AUTOSAR XML (schema 4-2-2)
package /STELLANTIS/EPT/ASWCs
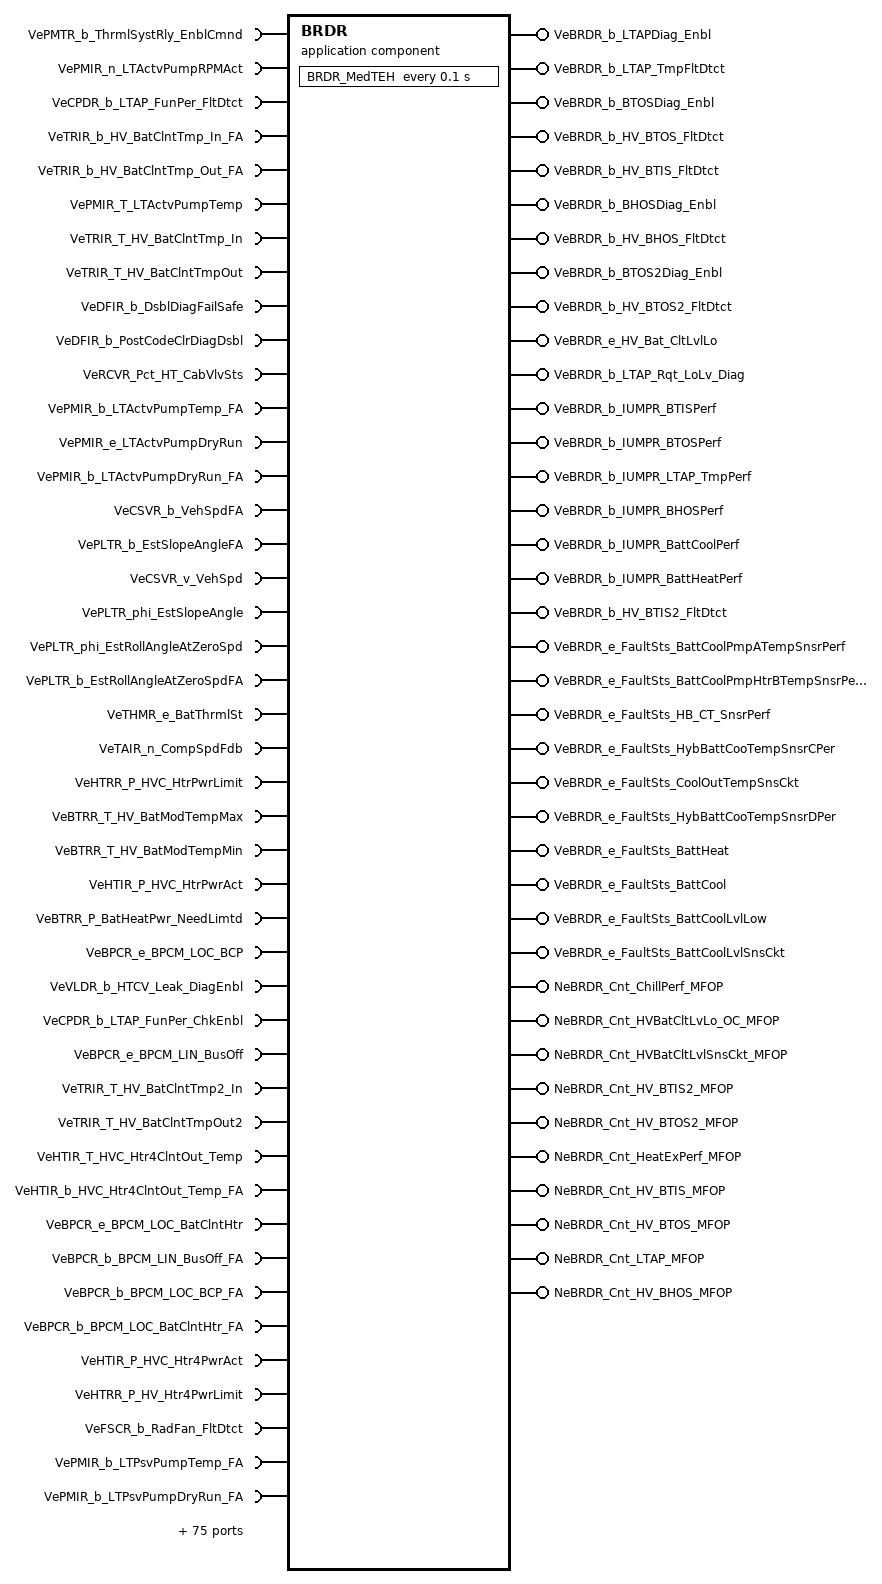
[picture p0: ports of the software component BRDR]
  application sw component type BRDR
    109 x require port:
      VePMTR_b_ThrmlSystRly_EnblCmnd: variation-point={short-label=vpVePMTR_b_ThrmlSystRly_EnblCmnd, sw-syscond=1}, nonqueued-receiver-com-spec{data-element=Value, init-value=0}, required-interface=VePMTR_b_ThrmlSystRly_EnblCmnd
      VePMIR_n_LTActvPumpRPMAct: variation-point={short-label=vpVePMIR_n_LTActvPumpRPMAct, sw-syscond=1}, nonqueued-receiver-com-spec{data-element=Value, init-value=0}, required-interface=VePMIR_n_LTActvPumpRPMAct
      VeCPDR_b_LTAP_FunPer_FltDtct: variation-point={short-label=vpVeCPDR_b_LTAP_FunPer_FltDtct, sw-syscond=1}, nonqueued-receiver-com-spec{data-element=Value, init-value=0}, required-interface=VeCPDR_b_LTAP_FunPer_FltDtct
      VeTRIR_b_HV_BatClntTmp_In_FA: variation-point={short-label=vpVeTRIR_b_HV_BatClntTmp_In_FA, sw-syscond=1}, nonqueued-receiver-com-spec{data-element=Value, init-value=0}, required-interface=VeTRIR_b_HV_BatClntTmp_In_FA
      VeTRIR_b_HV_BatClntTmp_Out_FA: variation-point={short-label=vpVeTRIR_b_HV_BatClntTmp_Out_FA, sw-syscond=1}, nonqueued-receiver-com-spec{data-element=Value, init-value=0}, required-interface=VeTRIR_b_HV_BatClntTmp_Out_FA
      VePMIR_T_LTActvPumpTemp: nonqueued-receiver-com-spec{data-element=Value, init-value=0}, required-interface=VePMIR_T_LTActvPumpTemp
      VeTRIR_T_HV_BatClntTmp_In: nonqueued-receiver-com-spec{data-element=Value, init-value=0}, required-interface=VeTRIR_T_HV_BatClntTmp_In
      VeTRIR_T_HV_BatClntTmpOut: nonqueued-receiver-com-spec{data-element=Value, init-value=0}, required-interface=VeTRIR_T_HV_BatClntTmpOut
      VeDFIR_b_DsblDiagFailSafe: variation-point={short-label=vpVeDFIR_b_DsblDiagFailSafe, sw-syscond=1}, nonqueued-receiver-com-spec{data-element=Value, init-value=0}, required-interface=VeDFIR_b_DsblDiagFailSafe
      VeDFIR_b_PostCodeClrDiagDsbl: variation-point={short-label=vpVeDFIR_b_PostCodeClrDiagDsbl, sw-syscond=1}, nonqueued-receiver-com-spec{data-element=Value, init-value=0}, required-interface=VeDFIR_b_PostCodeClrDiagDsbl
      VeRCVR_Pct_HT_CabVlvSts: variation-point={short-label=vpVeRCVR_Pct_HT_CabVlvSts, sw-syscond=1}, nonqueued-receiver-com-spec{data-element=Value, init-value=0}, required-interface=VeRCVR_Pct_HT_CabVlvSts
      VePMIR_b_LTActvPumpTemp_FA: variation-point={short-label=vpVePMIR_b_LTActvPumpTemp_FA, sw-syscond=1}, nonqueued-receiver-com-spec{data-element=Value, init-value=0}, required-interface=VePMIR_b_LTActvPumpTemp_FA
      VePMIR_e_LTActvPumpDryRun: variation-point={short-label=vpVePMIR_e_LTActvPumpDryRun, sw-syscond=1}, nonqueued-receiver-com-spec{data-element=Value, init-value=CePMPR_e_FTSNA_False}, required-interface=VePMIR_e_LTActvPumpDryRun
      VePMIR_b_LTActvPumpDryRun_FA: variation-point={short-label=vpVePMIR_b_LTActvPumpDryRun_FA, sw-syscond=1}, nonqueued-receiver-com-spec{data-element=Value, init-value=0}, required-interface=VePMIR_b_LTActvPumpDryRun_FA
      VeCSVR_b_VehSpdFA: variation-point={short-label=vpVeCSVR_b_VehSpdFA, sw-syscond=1}, nonqueued-receiver-com-spec{data-element=Value, init-value=0}, required-interface=VeCSVR_b_VehSpdFA
      VePLTR_b_EstSlopeAngleFA: variation-point={short-label=vpVePLTR_b_EstSlopeAngleFA, sw-syscond=1}, nonqueued-receiver-com-spec{data-element=Value, init-value=0}, required-interface=VePLTR_b_EstSlopeAngleFA
      VeCSVR_v_VehSpd: variation-point={short-label=vpVeCSVR_v_VehSpd, sw-syscond=1}, nonqueued-receiver-com-spec{data-element=Value, init-value=0}, required-interface=VeCSVR_v_VehSpd
      VePLTR_phi_EstSlopeAngle: variation-point={short-label=vpVePLTR_phi_EstSlopeAngle, sw-syscond=1}, nonqueued-receiver-com-spec{data-element=Value, init-value=0}, required-interface=VePLTR_phi_EstSlopeAngle
      VePLTR_phi_EstRollAngleAtZeroSpd: variation-point={short-label=vpVePLTR_phi_EstRollAngleAtZeroSpd, sw-syscond=1}, nonqueued-receiver-com-spec{data-element=Value, init-value=0}, required-interface=VePLTR_phi_EstRollAngleAtZeroSpd
      VePLTR_b_EstRollAngleAtZeroSpdFA: variation-point={short-label=vpVePLTR_b_EstRollAngleAtZeroSpdFA, sw-syscond=1}, nonqueued-receiver-com-spec{data-element=Value, init-value=0}, required-interface=VePLTR_b_EstRollAngleAtZeroSpdFA
      VeTHMR_e_BatThrmlSt: variation-point={short-label=vpVeTHMR_e_BatThrmlSt, sw-syscond=1}, nonqueued-receiver-com-spec{data-element=Value, init-value=CeTHMR_e_NoConditioning}, required-interface=VeTHMR_e_BatThrmlSt
      VeTAIR_n_CompSpdFdb: variation-point={short-label=vpVeTAIR_n_CompSpdFdb, sw-syscond=1}, nonqueued-receiver-com-spec{data-element=Value, init-value=0}, required-interface=VeTAIR_n_CompSpdFdb
      VeHTRR_P_HVC_HtrPwrLimit: variation-point={short-label=vpVeHTRR_P_HVC_HtrPwrLimit, sw-syscond=1}, nonqueued-receiver-com-spec{data-element=Value, init-value=0}, required-interface=VeHTRR_P_HVC_HtrPwrLimit
      VeBTRR_T_HV_BatModTempMax: variation-point={short-label=vpVeBTRR_T_HV_BatModTempMax, sw-syscond=1}, nonqueued-receiver-com-spec{data-element=Value, init-value=0}, required-interface=VeBTRR_T_HV_BatModTempMax
      VeBTRR_T_HV_BatModTempMin: variation-point={short-label=vpVeBTRR_T_HV_BatModTempMin, sw-syscond=1}, nonqueued-receiver-com-spec{data-element=Value, init-value=0}, required-interface=VeBTRR_T_HV_BatModTempMin
      VeHTIR_P_HVC_HtrPwrAct: variation-point={short-label=vpVeHTIR_P_HVC_HtrPwrAct, sw-syscond=1}, nonqueued-receiver-com-spec{data-element=Value, init-value=0}, required-interface=VeHTIR_P_HVC_HtrPwrAct
      VeBTRR_P_BatHeatPwr_NeedLimtd: variation-point={short-label=vpVeBTRR_P_BatHeatPwr_NeedLimtd, sw-syscond=1}, nonqueued-receiver-com-spec{data-element=Value, init-value=0}, required-interface=VeBTRR_P_BatHeatPwr_NeedLimtd
      VeBPCR_e_BPCM_LOC_BCP: variation-point={short-label=vpVeBPCR_e_BPCM_LOC_BCP, sw-syscond=1}, nonqueued-receiver-com-spec{data-element=Value, init-value=CeBPCR_e_LOC_BCP_False}, required-interface=VeBPCR_e_BPCM_LOC_BCP
      VeVLDR_b_HTCV_Leak_DiagEnbl: variation-point={short-label=vpVeVLDR_b_HTCV_Leak_DiagEnbl, sw-syscond=1}, nonqueued-receiver-com-spec{data-element=Value, init-value=0}, required-interface=VeVLDR_b_HTCV_Leak_DiagEnbl
      VeCPDR_b_LTAP_FunPer_ChkEnbl: variation-point={short-label=vpVeCPDR_b_LTAP_FunPer_ChkEnbl, sw-syscond=1}, nonqueued-receiver-com-spec{data-element=Value, init-value=0}, required-interface=VeCPDR_b_LTAP_FunPer_ChkEnbl
      VeBPCR_e_BPCM_LIN_BusOff: variation-point={short-label=vpVeBPCR_e_BPCM_LIN_BusOff, sw-syscond=1}, nonqueued-receiver-com-spec{data-element=Value, init-value=CeBPCR_e_LIN_BusOff_Disabled}, required-interface=VeBPCR_e_BPCM_LIN_BusOff
      VeTRIR_T_HV_BatClntTmp2_In: nonqueued-receiver-com-spec{data-element=Value, init-value=0}, required-interface=VeTRIR_T_HV_BatClntTmp2_In
      VeTRIR_T_HV_BatClntTmpOut2: nonqueued-receiver-com-spec{data-element=Value, init-value=0}, required-interface=VeTRIR_T_HV_BatClntTmpOut2
      VeHTIR_T_HVC_Htr4ClntOut_Temp: nonqueued-receiver-com-spec{data-element=Value, init-value=0}, required-interface=VeHTIR_T_HVC_Htr4ClntOut_Temp
      VeHTIR_b_HVC_Htr4ClntOut_Temp_FA: variation-point={short-label=vpVeHTIR_b_HVC_Htr4ClntOut_Temp_FA, sw-syscond=1}, nonqueued-receiver-com-spec{data-element=Value, init-value=0}, required-interface=VeHTIR_b_HVC_Htr4ClntOut_Temp_FA
      VeBPCR_e_BPCM_LOC_BatClntHtr: variation-point={short-label=vpVeBPCR_e_BPCM_LOC_BatClntHtr, sw-syscond=1}, nonqueued-receiver-com-spec{data-element=Value, init-value=CeBPCR_e_LOC_BatClntHtr_False}, required-interface=VeBPCR_e_BPCM_LOC_BatClntHtr
      VeBPCR_b_BPCM_LIN_BusOff_FA: variation-point={short-label=vpVeBPCR_b_BPCM_LIN_BusOff_FA, sw-syscond=1}, nonqueued-receiver-com-spec{data-element=Value, init-value=0}, required-interface=VeBPCR_b_BPCM_LIN_BusOff_FA
      VeBPCR_b_BPCM_LOC_BCP_FA: variation-point={short-label=vpVeBPCR_b_BPCM_LOC_BCP_FA, sw-syscond=1}, nonqueued-receiver-com-spec{data-element=Value, init-value=0}, required-interface=VeBPCR_b_BPCM_LOC_BCP_FA
      VeBPCR_b_BPCM_LOC_BatClntHtr_FA: variation-point={short-label=vpVeBPCR_b_BPCM_LOC_BatClntHtr_FA, sw-syscond=1}, nonqueued-receiver-com-spec{data-element=Value, init-value=0}, required-interface=VeBPCR_b_BPCM_LOC_BatClntHtr_FA
      VeHTIR_P_HVC_Htr4PwrAct: variation-point={short-label=vpVeHTIR_P_HVC_Htr4PwrAct, sw-syscond=1}, nonqueued-receiver-com-spec{data-element=Value, init-value=0}, required-interface=VeHTIR_P_HVC_Htr4PwrAct
      VeHTRR_P_HV_Htr4PwrLimit: variation-point={short-label=vpVeHTRR_P_HV_Htr4PwrLimit, sw-syscond=1}, nonqueued-receiver-com-spec{data-element=Value, init-value=0}, required-interface=VeHTRR_P_HV_Htr4PwrLimit
      VeFSCR_b_RadFan_FltDtct: variation-point={short-label=vpVeFSCR_b_RadFan_FltDtct, sw-syscond=1}, nonqueued-receiver-com-spec{data-element=Value, init-value=0}, required-interface=VeFSCR_b_RadFan_FltDtct
      VePMIR_b_LTPsvPumpTemp_FA: variation-point={short-label=vpVePMIR_b_LTPsvPumpTemp_FA, sw-syscond=1}, nonqueued-receiver-com-spec{data-element=Value, init-value=0}, required-interface=VePMIR_b_LTPsvPumpTemp_FA
      VePMIR_b_LTPsvPumpDryRun_FA: variation-point={short-label=vpVePMIR_b_LTPsvPumpDryRun_FA, sw-syscond=1}, nonqueued-receiver-com-spec{data-element=Value, init-value=0}, required-interface=VePMIR_b_LTPsvPumpDryRun_FA
      VeAATR_T_EstAmbAirTemp: variation-point={short-label=vpVeAATR_T_EstAmbAirTemp, sw-syscond=1}, nonqueued-receiver-com-spec{data-element=Value, init-value=0}, required-interface=VeAATR_T_EstAmbAirTemp
      VeTAIR_Pct_FrWyVlv_PstnAct: variation-point={short-label=vpVeTAIR_Pct_FrWyVlv_PstnAct, sw-syscond=1}, nonqueued-receiver-com-spec{data-element=Value, init-value=0}, required-interface=VeTAIR_Pct_FrWyVlv_PstnAct
      VeTMIR_T_OnBrdChrg_ClntTmpIn: variation-point={short-label=vpVeTMIR_T_OnBrdChrg_ClntTmpIn, sw-syscond=1}, nonqueued-receiver-com-spec{data-element=Value, init-value=0}, required-interface=VeTMIR_T_OnBrdChrg_ClntTmpIn
      VeDFIR_b_IsDiagGlobalConditionsValid: variation-point={short-label=vpVeDFIR_b_IsDiagGlobalConditionsValid, sw-syscond=1}, nonqueued-receiver-com-spec{data-element=Value, init-value=0}, required-interface=VeDFIR_b_IsDiagGlobalConditionsValid
      VeTRIR_U_BatBotlClnt_LoLvlVolt: variation-point={short-label=vpVeTRIR_U_BatBotlClnt_LoLvlVolt, sw-syscond=1}, nonqueued-receiver-com-spec{data-element=Value, init-value=0}, required-interface=VeTRIR_U_BatBotlClnt_LoLvlVolt
      VeDMAB_y_StatusByte_CommBusOff: nonqueued-receiver-com-spec{data-element=Value, init-value=0}, required-interface=VeDMAB_y_StatusByte_CommBusOff
      VeDMAB_y_StatusByte_CommBus_B_Off: nonqueued-receiver-com-spec{data-element=Value, init-value=0}, required-interface=VeDMAB_y_StatusByte_CommBus_B_Off
      VeDMAB_y_StatusByte_InvData_BECM_CANC11: nonqueued-receiver-com-spec{data-element=Value, init-value=0}, required-interface=VeDMAB_y_StatusByte_InvData_BECM_CANC11
      VeDMAB_y_StatusByte_InvData_BECM: nonqueued-receiver-com-spec{data-element=Value, init-value=0}, required-interface=VeDMAB_y_StatusByte_InvData_BECM
      VeDMAB_y_StatusByte_LosCommBECM_A_CANC11: nonqueued-receiver-com-spec{data-element=Value, init-value=0}, required-interface=VeDMAB_y_StatusByte_LosCommBECM_A_CANC11
      VeDMAB_y_StatusByte_LosCommBECM_A: nonqueued-receiver-com-spec{data-element=Value, init-value=0}, required-interface=VeDMAB_y_StatusByte_LosCommBECM_A
      VeDMAB_y_StatusByte_AC_RefrigPresSnsrAHi: nonqueued-receiver-com-spec{data-element=Value, init-value=0}, required-interface=VeDMAB_y_StatusByte_AC_RefrigPresSnsrAHi
      VeDMAB_y_StatusByte_AC_RefrigPresSnsrALo: nonqueued-receiver-com-spec{data-element=Value, init-value=0}, required-interface=VeDMAB_y_StatusByte_AC_RefrigPresSnsrALo
      VeDMAB_y_StatusByte_BattCoolLvlSnsCkt: nonqueued-receiver-com-spec{data-element=Value, init-value=0}, required-interface=VeDMAB_y_StatusByte_BattCoolLvlSnsCkt
      VeDMAB_y_StatusByte_CT_SnsrCktHi: nonqueued-receiver-com-spec{data-element=Value, init-value=0}, required-interface=VeDMAB_y_StatusByte_CT_SnsrCktHi
      VeDMAB_y_StatusByte_CT_SnsrCktLo: nonqueued-receiver-com-spec{data-element=Value, init-value=0}, required-interface=VeDMAB_y_StatusByte_CT_SnsrCktLo
      VeDMAB_y_StatusByte_CoolCtrlVlv1CktHi: nonqueued-receiver-com-spec{data-element=Value, init-value=0}, required-interface=VeDMAB_y_StatusByte_CoolCtrlVlv1CktHi
      VeDMAB_y_StatusByte_CoolCtrlVlv1CktLo: nonqueued-receiver-com-spec{data-element=Value, init-value=0}, required-interface=VeDMAB_y_StatusByte_CoolCtrlVlv1CktLo
      VeDMAB_y_StatusByte_CoolCtrlVlv1Ckt: nonqueued-receiver-com-spec{data-element=Value, init-value=0}, required-interface=VeDMAB_y_StatusByte_CoolCtrlVlv1Ckt
      VeDMAB_y_StatusByte_HybBatPacCooInlTemSenCirHig: nonqueued-receiver-com-spec{data-element=Value, init-value=0}, required-interface=VeDMAB_y_StatusByte_HybBatPacCooInlTemSenCirHig
      VeDMAB_y_StatusByte_HybBatPacCooInlTemSenCirLow: nonqueued-receiver-com-spec{data-element=Value, init-value=0}, required-interface=VeDMAB_y_StatusByte_HybBatPacCooInlTemSenCirLow
      VeDMAB_y_StatusByte_HybBatPacCooOutTemSenCirHig: nonqueued-receiver-com-spec{data-element=Value, init-value=0}, required-interface=VeDMAB_y_StatusByte_HybBatPacCooOutTemSenCirHig
      VeDMAB_y_StatusByte_HybBatPacCooOutTemSenCir: nonqueued-receiver-com-spec{data-element=Value, init-value=0}, required-interface=VeDMAB_y_StatusByte_HybBatPacCooOutTemSenCir
      VeDMAB_y_StatusByte_MtrElect_CT_SnsrCktHi: nonqueued-receiver-com-spec{data-element=Value, init-value=0}, required-interface=VeDMAB_y_StatusByte_MtrElect_CT_SnsrCktHi
      VeDMAB_y_StatusByte_MtrElect_CT_SnsrCktLo: nonqueued-receiver-com-spec{data-element=Value, init-value=0}, required-interface=VeDMAB_y_StatusByte_MtrElect_CT_SnsrCktLo
      VeDMAB_y_StatusByte_BattCoolPmpOveSpd: nonqueued-receiver-com-spec{data-element=Value, init-value=0}, required-interface=VeDMAB_y_StatusByte_BattCoolPmpOveSpd
      VeDMAB_y_StatusByte_CoolantVlvA_StkOpn: nonqueued-receiver-com-spec{data-element=Value, init-value=0}, required-interface=VeDMAB_y_StatusByte_CoolantVlvA_StkOpn
      VeDMAB_y_StatusByte_BattCoolPmpATempSnsrPerf: nonqueued-receiver-com-spec{data-element=Value, init-value=0}, required-interface=VeDMAB_y_StatusByte_BattCoolPmpATempSnsrPerf
      VeDMAB_y_StatusByte_BattCoolPmpHtrBTempSnsrPerf: nonqueued-receiver-com-spec{data-element=Value, init-value=0}, required-interface=VeDMAB_y_StatusByte_BattCoolPmpHtrBTempSnsrPerf
      VeDMAB_y_StatusByte_CoolOutTempSnsCkt: nonqueued-receiver-com-spec{data-element=Value, init-value=0}, required-interface=VeDMAB_y_StatusByte_CoolOutTempSnsCkt
      VeDMAB_y_StatusByte_HB_CT_SnsrPerf: nonqueued-receiver-com-spec{data-element=Value, init-value=0}, required-interface=VeDMAB_y_StatusByte_HB_CT_SnsrPerf
      VeDMAB_y_StatusByte_HybBattCooTempSnsrCPer: nonqueued-receiver-com-spec{data-element=Value, init-value=0}, required-interface=VeDMAB_y_StatusByte_HybBattCooTempSnsrCPer
      VeDMAB_y_StatusByte_HybBattCooTempSnsrDPer: nonqueued-receiver-com-spec{data-element=Value, init-value=0}, required-interface=VeDMAB_y_StatusByte_HybBattCooTempSnsrDPer
      VeDMAB_y_StatusByte_LIN1_BusOff: nonqueued-receiver-com-spec{data-element=Value, init-value=0}, required-interface=VeDMAB_y_StatusByte_LIN1_BusOff
      VeDMAB_y_StatusByte_LostCommHB_CoolPmp: nonqueued-receiver-com-spec{data-element=Value, init-value=0}, required-interface=VeDMAB_y_StatusByte_LostCommHB_CoolPmp
      VeDMAB_y_StatusByte_CoolantHeaterBPerf: nonqueued-receiver-com-spec{data-element=Value, init-value=0}, required-interface=VeDMAB_y_StatusByte_CoolantHeaterBPerf
      VeDMAB_y_StatusByte_LIN2_BusOff: nonqueued-receiver-com-spec{data-element=Value, init-value=0}, required-interface=VeDMAB_y_StatusByte_LIN2_BusOff
      VeDMAB_y_StatusByte_LostCommHB_CooltHtr4: nonqueued-receiver-com-spec{data-element=Value, init-value=0}, required-interface=VeDMAB_y_StatusByte_LostCommHB_CooltHtr4
      VeDMAB_y_StatusByte_LostCommECM_A_BusB: nonqueued-receiver-com-spec{data-element=Value, init-value=0}, required-interface=VeDMAB_y_StatusByte_LostCommECM_A_BusB
      VeDMAB_y_StatusByte_BattCoolLvlLow: nonqueued-receiver-com-spec{data-element=Value, init-value=0}, required-interface=VeDMAB_y_StatusByte_BattCoolLvlLow
      VeDMAB_y_StatusByte_BattCoolPmpPerf: nonqueued-receiver-com-spec{data-element=Value, init-value=0}, required-interface=VeDMAB_y_StatusByte_BattCoolPmpPerf
      VeDMAB_y_StatusByte_ThrmlRlyCtrlCkt: nonqueued-receiver-com-spec{data-element=Value, init-value=0}, required-interface=VeDMAB_y_StatusByte_ThrmlRlyCtrlCkt
      VeDMAB_y_StatusByte_CoolHeaterAPerf: nonqueued-receiver-com-spec{data-element=Value, init-value=0}, required-interface=VeDMAB_y_StatusByte_CoolHeaterAPerf
      VeDMAB_y_StatusByte_CoolantVlvA_Perf: nonqueued-receiver-com-spec{data-element=Value, init-value=0}, required-interface=VeDMAB_y_StatusByte_CoolantVlvA_Perf
      VeDMAB_y_StatusByte_HB_PSC_CtrlValACktPerf: nonqueued-receiver-com-spec{data-element=Value, init-value=0}, required-interface=VeDMAB_y_StatusByte_HB_PSC_CtrlValACktPerf
      VeDMAB_y_StatusByte_LosCommHybPSCCtrlValA: nonqueued-receiver-com-spec{data-element=Value, init-value=0}, required-interface=VeDMAB_y_StatusByte_LosCommHybPSCCtrlValA
      VeDMAB_y_StatusByte_CT_SnsrPerf: nonqueued-receiver-com-spec{data-element=Value, init-value=0}, required-interface=VeDMAB_y_StatusByte_CT_SnsrPerf
      VeDMAB_y_StatusByte_HeatingElmntPerf: nonqueued-receiver-com-spec{data-element=Value, init-value=0}, required-interface=VeDMAB_y_StatusByte_HeatingElmntPerf
      VeDMAB_y_StatusByte_AC_RefrigPresSnsrAPerf: nonqueued-receiver-com-spec{data-element=Value, init-value=0}, required-interface=VeDMAB_y_StatusByte_AC_RefrigPresSnsrAPerf
      VeDMAB_y_StatusByte_EACPerf: nonqueued-receiver-com-spec{data-element=Value, init-value=0}, required-interface=VeDMAB_y_StatusByte_EACPerf
      VeDMAB_y_StatusByte_LostCommEAC: nonqueued-receiver-com-spec{data-element=Value, init-value=0}, required-interface=VeDMAB_y_StatusByte_LostCommEAC
      VeDMAB_y_StatusByte_LIN3_BusOff: nonqueued-receiver-com-spec{data-element=Value, init-value=0}, required-interface=VeDMAB_y_StatusByte_LIN3_BusOff
      VeDMAB_y_StatusByte_AC_RefrigExpVlvActCtrCktPerf: nonqueued-receiver-com-spec{data-element=Value, init-value=0}, required-interface=VeDMAB_y_StatusByte_AC_RefrigExpVlvActCtrCktPerf
      VeDMAB_y_StatusByte_LostCommMtrElectCoolPmpA: nonqueued-receiver-com-spec{data-element=Value, init-value=0}, required-interface=VeDMAB_y_StatusByte_LostCommMtrElectCoolPmpA
      VeDMAB_y_StatusByte_MtrElect_CT_SnsrPerf: nonqueued-receiver-com-spec{data-element=Value, init-value=0}, required-interface=VeDMAB_y_StatusByte_MtrElect_CT_SnsrPerf
      VeDMAB_y_StatusByte_MtrElect_CoolPmpATempSnsrPerf: nonqueued-receiver-com-spec{data-element=Value, init-value=0}, required-interface=VeDMAB_y_StatusByte_MtrElect_CoolPmpATempSnsrPerf
      VeDMAB_y_StatusByte_MtrElect_CoolPumAOvrSpd: nonqueued-receiver-com-spec{data-element=Value, init-value=0}, required-interface=VeDMAB_y_StatusByte_MtrElect_CoolPumAOvrSpd
      VeDMAB_y_StatusByte_HiSpdFD_CAN11CommBus: nonqueued-receiver-com-spec{data-element=Value, init-value=0}, required-interface=VeDMAB_y_StatusByte_HiSpdFD_CAN11CommBus
      VeDMAB_y_StatusByte_HiSpdFD_CAN5CommBus: nonqueued-receiver-com-spec{data-element=Value, init-value=0}, required-interface=VeDMAB_y_StatusByte_HiSpdFD_CAN5CommBus
      VeDMAB_y_StatusByte_HiSpdFD_CAN3CommBus: nonqueued-receiver-com-spec{data-element=Value, init-value=0}, required-interface=VeDMAB_y_StatusByte_HiSpdFD_CAN3CommBus
      VeDMAB_y_StatusByte_HiSpdFD_CAN11CommBusPerf: nonqueued-receiver-com-spec{data-element=Value, init-value=0}, required-interface=VeDMAB_y_StatusByte_HiSpdFD_CAN11CommBusPerf
      VeDMAB_y_StatusByte_HiSpdFD_CAN5CommBusPerf: nonqueued-receiver-com-spec{data-element=Value, init-value=0}, required-interface=VeDMAB_y_StatusByte_HiSpdFD_CAN5CommBusPerf
      VeDMAB_y_StatusByte_HiSpdFD_CAN3CommBusPerf: nonqueued-receiver-com-spec{data-element=Value, init-value=0}, required-interface=VeDMAB_y_StatusByte_HiSpdFD_CAN3CommBusPerf
      VeDMAB_y_StatusByte_BattCool: nonqueued-receiver-com-spec{data-element=Value, init-value=0}, required-interface=VeDMAB_y_StatusByte_BattCool
      VeDMAB_y_StatusByte_BattHeat: nonqueued-receiver-com-spec{data-element=Value, init-value=0}, required-interface=VeDMAB_y_StatusByte_BattHeat
    28 x provide port:
      VeBRDR_b_LTAPDiag_Enbl: nonqueued-sender-com-spec{data-element=Value, init-value=0}, provided-interface=VeBRDR_b_LTAPDiag_Enbl
      VeBRDR_b_LTAP_TmpFltDtct: nonqueued-sender-com-spec{data-element=Value, init-value=0}, provided-interface=VeBRDR_b_LTAP_TmpFltDtct
      VeBRDR_b_BTOSDiag_Enbl: nonqueued-sender-com-spec{data-element=Value, init-value=0}, provided-interface=VeBRDR_b_BTOSDiag_Enbl
      VeBRDR_b_HV_BTOS_FltDtct: nonqueued-sender-com-spec{data-element=Value, init-value=0}, provided-interface=VeBRDR_b_HV_BTOS_FltDtct
      VeBRDR_b_HV_BTIS_FltDtct: nonqueued-sender-com-spec{data-element=Value, init-value=0}, provided-interface=VeBRDR_b_HV_BTIS_FltDtct
      VeBRDR_b_BHOSDiag_Enbl: nonqueued-sender-com-spec{data-element=Value, init-value=0}, provided-interface=VeBRDR_b_BHOSDiag_Enbl
      VeBRDR_b_HV_BHOS_FltDtct: nonqueued-sender-com-spec{data-element=Value, init-value=0}, provided-interface=VeBRDR_b_HV_BHOS_FltDtct
      VeBRDR_b_BTOS2Diag_Enbl: nonqueued-sender-com-spec{data-element=Value, init-value=0}, provided-interface=VeBRDR_b_BTOS2Diag_Enbl
      VeBRDR_b_HV_BTOS2_FltDtct: nonqueued-sender-com-spec{data-element=Value, init-value=0}, provided-interface=VeBRDR_b_HV_BTOS2_FltDtct
      VeBRDR_e_HV_Bat_CltLvlLo: nonqueued-sender-com-spec{data-element=Value, init-value=CeBRDR_e_BatCltLvlNotLo}, provided-interface=VeBRDR_e_HV_Bat_CltLvlLo
      VeBRDR_b_LTAP_Rqt_LoLv_Diag: nonqueued-sender-com-spec{data-element=Value, init-value=0}, provided-interface=VeBRDR_b_LTAP_Rqt_LoLv_Diag
      VeBRDR_b_IUMPR_BTISPerf: nonqueued-sender-com-spec{data-element=Value, init-value=0}, provided-interface=VeBRDR_b_IUMPR_BTISPerf
      VeBRDR_b_IUMPR_BTOSPerf: nonqueued-sender-com-spec{data-element=Value, init-value=0}, provided-interface=VeBRDR_b_IUMPR_BTOSPerf
      VeBRDR_b_IUMPR_LTAP_TmpPerf: nonqueued-sender-com-spec{data-element=Value, init-value=0}, provided-interface=VeBRDR_b_IUMPR_LTAP_TmpPerf
      VeBRDR_b_IUMPR_BHOSPerf: nonqueued-sender-com-spec{data-element=Value, init-value=0}, provided-interface=VeBRDR_b_IUMPR_BHOSPerf
      VeBRDR_b_IUMPR_BattCoolPerf: nonqueued-sender-com-spec{data-element=Value, init-value=0}, provided-interface=VeBRDR_b_IUMPR_BattCoolPerf
      VeBRDR_b_IUMPR_BattHeatPerf: nonqueued-sender-com-spec{data-element=Value, init-value=0}, provided-interface=VeBRDR_b_IUMPR_BattHeatPerf
      VeBRDR_b_HV_BTIS2_FltDtct: nonqueued-sender-com-spec{data-element=Value, init-value=0}, provided-interface=VeBRDR_b_HV_BTIS2_FltDtct
      VeBRDR_e_FaultSts_BattCoolPmpATempSnsrPerf: nonqueued-sender-com-spec{data-element=Value, init-value=CeDFIB_e_Init}, provided-interface=VeBRDR_e_FaultSts_BattCoolPmpATempSnsrPerf
      VeBRDR_e_FaultSts_BattCoolPmpHtrBTempSnsrPerf: nonqueued-sender-com-spec{data-element=Value, init-value=CeDFIB_e_Init}, provided-interface=VeBRDR_e_FaultSts_BattCoolPmpHtrBTempSnsrPerf
      VeBRDR_e_FaultSts_HB_CT_SnsrPerf: nonqueued-sender-com-spec{data-element=Value, init-value=CeDFIB_e_Init}, provided-interface=VeBRDR_e_FaultSts_HB_CT_SnsrPerf
      VeBRDR_e_FaultSts_HybBattCooTempSnsrCPer: nonqueued-sender-com-spec{data-element=Value, init-value=CeDFIB_e_Init}, provided-interface=VeBRDR_e_FaultSts_HybBattCooTempSnsrCPer
      VeBRDR_e_FaultSts_CoolOutTempSnsCkt: nonqueued-sender-com-spec{data-element=Value, init-value=CeDFIB_e_Init}, provided-interface=VeBRDR_e_FaultSts_CoolOutTempSnsCkt
      VeBRDR_e_FaultSts_HybBattCooTempSnsrDPer: nonqueued-sender-com-spec{data-element=Value, init-value=CeDFIB_e_Init}, provided-interface=VeBRDR_e_FaultSts_HybBattCooTempSnsrDPer
      VeBRDR_e_FaultSts_BattHeat: nonqueued-sender-com-spec{data-element=Value, init-value=CeDFIB_e_Init}, provided-interface=VeBRDR_e_FaultSts_BattHeat
      VeBRDR_e_FaultSts_BattCool: nonqueued-sender-com-spec{data-element=Value, init-value=CeDFIB_e_Init}, provided-interface=VeBRDR_e_FaultSts_BattCool
      VeBRDR_e_FaultSts_BattCoolLvlLow: nonqueued-sender-com-spec{data-element=Value, init-value=CeDFIB_e_Init}, provided-interface=VeBRDR_e_FaultSts_BattCoolLvlLow
      VeBRDR_e_FaultSts_BattCoolLvlSnsCkt: nonqueued-sender-com-spec{data-element=Value, init-value=CeDFIB_e_Init}, provided-interface=VeBRDR_e_FaultSts_BattCoolLvlSnsCkt
    10 x require port:
      NeBRDR_Cnt_ChillPerf_MFOP_Rx: nv-require-com-spec{init-value=0, variable=NeBRDR_Cnt_ChillPerf_MFOP}, required-interface=NeBRDR_Cnt_ChillPerf_MFOP
      NeBRDR_Cnt_HVBatCltLvLo_OC_MFOP_Rx: nv-require-com-spec{init-value=0, variable=NeBRDR_Cnt_HVBatCltLvLo_OC_MFOP}, required-interface=NeBRDR_Cnt_HVBatCltLvLo_OC_MFOP
      NeBRDR_Cnt_HVBatCltLvlSnsCkt_MFOP_Rx: nv-require-com-spec{init-value=0, variable=NeBRDR_Cnt_HVBatCltLvlSnsCkt_MFOP}, required-interface=NeBRDR_Cnt_HVBatCltLvlSnsCkt_MFOP
      NeBRDR_Cnt_HV_BTIS2_MFOP_Rx: nv-require-com-spec{init-value=0, variable=NeBRDR_Cnt_HV_BTIS2_MFOP}, required-interface=NeBRDR_Cnt_HV_BTIS2_MFOP
      NeBRDR_Cnt_HV_BTOS2_MFOP_Rx: nv-require-com-spec{init-value=0, variable=NeBRDR_Cnt_HV_BTOS2_MFOP}, required-interface=NeBRDR_Cnt_HV_BTOS2_MFOP
      NeBRDR_Cnt_HeatExPerf_MFOP_Rx: nv-require-com-spec{init-value=0, variable=NeBRDR_Cnt_HeatExPerf_MFOP}, required-interface=NeBRDR_Cnt_HeatExPerf_MFOP
      NeBRDR_Cnt_HV_BTIS_MFOP_Rx: nv-require-com-spec{init-value=0, variable=NeBRDR_Cnt_HV_BTIS_MFOP}, required-interface=NeBRDR_Cnt_HV_BTIS_MFOP
      NeBRDR_Cnt_HV_BTOS_MFOP_Rx: nv-require-com-spec{init-value=0, variable=NeBRDR_Cnt_HV_BTOS_MFOP}, required-interface=NeBRDR_Cnt_HV_BTOS_MFOP
      NeBRDR_Cnt_LTAP_MFOP_Rx: nv-require-com-spec{init-value=0, variable=NeBRDR_Cnt_LTAP_MFOP}, required-interface=NeBRDR_Cnt_LTAP_MFOP
      NeBRDR_Cnt_HV_BHOS_MFOP_Rx: nv-require-com-spec{init-value=0, variable=NeBRDR_Cnt_HV_BHOS_MFOP}, required-interface=NeBRDR_Cnt_HV_BHOS_MFOP
    10 x provide port:
      NeBRDR_Cnt_ChillPerf_MFOP: nv-provide-com-spec{ram-block-init-value=0, variable=NeBRDR_Cnt_ChillPerf_MFOP}, provided-interface=NeBRDR_Cnt_ChillPerf_MFOP
      NeBRDR_Cnt_HVBatCltLvLo_OC_MFOP: nv-provide-com-spec{ram-block-init-value=0, variable=NeBRDR_Cnt_HVBatCltLvLo_OC_MFOP}, provided-interface=NeBRDR_Cnt_HVBatCltLvLo_OC_MFOP
      NeBRDR_Cnt_HVBatCltLvlSnsCkt_MFOP: nv-provide-com-spec{ram-block-init-value=0, variable=NeBRDR_Cnt_HVBatCltLvlSnsCkt_MFOP}, provided-interface=NeBRDR_Cnt_HVBatCltLvlSnsCkt_MFOP
      NeBRDR_Cnt_HV_BTIS2_MFOP: nv-provide-com-spec{ram-block-init-value=0, variable=NeBRDR_Cnt_HV_BTIS2_MFOP}, provided-interface=NeBRDR_Cnt_HV_BTIS2_MFOP
      NeBRDR_Cnt_HV_BTOS2_MFOP: nv-provide-com-spec{ram-block-init-value=0, variable=NeBRDR_Cnt_HV_BTOS2_MFOP}, provided-interface=NeBRDR_Cnt_HV_BTOS2_MFOP
      NeBRDR_Cnt_HeatExPerf_MFOP: nv-provide-com-spec{ram-block-init-value=0, variable=NeBRDR_Cnt_HeatExPerf_MFOP}, provided-interface=NeBRDR_Cnt_HeatExPerf_MFOP
      NeBRDR_Cnt_HV_BTIS_MFOP: nv-provide-com-spec{ram-block-init-value=0, variable=NeBRDR_Cnt_HV_BTIS_MFOP}, provided-interface=NeBRDR_Cnt_HV_BTIS_MFOP
      NeBRDR_Cnt_HV_BTOS_MFOP: nv-provide-com-spec{ram-block-init-value=0, variable=NeBRDR_Cnt_HV_BTOS_MFOP}, provided-interface=NeBRDR_Cnt_HV_BTOS_MFOP
      NeBRDR_Cnt_LTAP_MFOP: nv-provide-com-spec{ram-block-init-value=0, variable=NeBRDR_Cnt_LTAP_MFOP}, provided-interface=NeBRDR_Cnt_LTAP_MFOP
      NeBRDR_Cnt_HV_BHOS_MFOP: nv-provide-com-spec{ram-block-init-value=0, variable=NeBRDR_Cnt_HV_BHOS_MFOP}, provided-interface=NeBRDR_Cnt_HV_BHOS_MFOP
    behavior IB_BRDR: data-type-mapping=msADTtoIDTMapping, handle-termination-and-restart=NO-SUPPORT
      timing event Event_MedTEH: start-on-event=BRDR_MedTEH, period=0.1
      init event Event_BRDR_ac_Init: start-on-event=BRDR_ac_Init
      init event Event_PwrOn: start-on-event=BRDR_PwrOn
      init event Event_PwrOff: start-on-event=BRDR_PwrOff
      4 x runnable:
        BRDR_ac_Init
          data-send-points:
            11 x access:
              OUT_VeBRDR_e_HV_Bat_CltLvlLo_Value: accessed-variable=VeBRDR_e_HV_Bat_CltLvlLo.Value
              OUT_VeBRDR_e_FaultSts_BattCoolPmpATempSnsrPerf_Value: accessed-variable=VeBRDR_e_FaultSts_BattCoolPmpATempSnsrPerf.Value
              OUT_VeBRDR_e_FaultSts_BattCoolPmpHtrBTempSnsrPerf_Value: accessed-variable=VeBRDR_e_FaultSts_BattCoolPmpHtrBTempSnsrPerf.Value
              OUT_VeBRDR_e_FaultSts_HB_CT_SnsrPerf_Value: accessed-variable=VeBRDR_e_FaultSts_HB_CT_SnsrPerf.Value
              OUT_VeBRDR_e_FaultSts_HybBattCooTempSnsrCPer_Value: accessed-variable=VeBRDR_e_FaultSts_HybBattCooTempSnsrCPer.Value
              OUT_VeBRDR_e_FaultSts_CoolOutTempSnsCkt_Value: accessed-variable=VeBRDR_e_FaultSts_CoolOutTempSnsCkt.Value
              OUT_VeBRDR_e_FaultSts_HybBattCooTempSnsrDPer_Value: accessed-variable=VeBRDR_e_FaultSts_HybBattCooTempSnsrDPer.Value
              OUT_VeBRDR_e_FaultSts_BattHeat_Value: accessed-variable=VeBRDR_e_FaultSts_BattHeat.Value
              OUT_VeBRDR_e_FaultSts_BattCool_Value: accessed-variable=VeBRDR_e_FaultSts_BattCool.Value
              OUT_VeBRDR_e_FaultSts_BattCoolLvlLow_Value: accessed-variable=VeBRDR_e_FaultSts_BattCoolLvlLow.Value
              OUT_VeBRDR_e_FaultSts_BattCoolLvlSnsCkt_Value: accessed-variable=VeBRDR_e_FaultSts_BattCoolLvlSnsCkt.Value
        BRDR_MedTEH
          data-receive-point-by-arguments:
            109 x access:
              IN_VeAATR_T_EstAmbAirTemp_Value: accessed-variable=VeAATR_T_EstAmbAirTemp.Value, variation-point={short-label=vpIN_VeAATR_T_EstAmbAirTemp_Value, sw-syscond=1}
              IN_VeBPCR_b_BPCM_LIN_BusOff_FA_Value: accessed-variable=VeBPCR_b_BPCM_LIN_BusOff_FA.Value, variation-point={short-label=vpIN_VeBPCR_b_BPCM_LIN_BusOff_FA_Value, sw-syscond=1}
              IN_VeBPCR_b_BPCM_LOC_BCP_FA_Value: accessed-variable=VeBPCR_b_BPCM_LOC_BCP_FA.Value, variation-point={short-label=vpIN_VeBPCR_b_BPCM_LOC_BCP_FA_Value, sw-syscond=1}
              IN_VeBPCR_b_BPCM_LOC_BatClntHtr_FA_Value: accessed-variable=VeBPCR_b_BPCM_LOC_BatClntHtr_FA.Value, variation-point={short-label=vpIN_VeBPCR_b_BPCM_LOC_BatClntHtr_FA_Value, sw-syscond=1}
              IN_VeBPCR_e_BPCM_LIN_BusOff_Value: accessed-variable=VeBPCR_e_BPCM_LIN_BusOff.Value, variation-point={short-label=vpIN_VeBPCR_e_BPCM_LIN_BusOff_Value, sw-syscond=1}
              IN_VeBPCR_e_BPCM_LOC_BCP_Value: accessed-variable=VeBPCR_e_BPCM_LOC_BCP.Value, variation-point={short-label=vpIN_VeBPCR_e_BPCM_LOC_BCP_Value, sw-syscond=1}
              IN_VeBPCR_e_BPCM_LOC_BatClntHtr_Value: accessed-variable=VeBPCR_e_BPCM_LOC_BatClntHtr.Value, variation-point={short-label=vpIN_VeBPCR_e_BPCM_LOC_BatClntHtr_Value, sw-syscond=1}
              IN_VeBTRR_P_BatHeatPwr_NeedLimtd_Value: accessed-variable=VeBTRR_P_BatHeatPwr_NeedLimtd.Value, variation-point={short-label=vpIN_VeBTRR_P_BatHeatPwr_NeedLimtd_Value, sw-syscond=1}
              IN_VeBTRR_T_HV_BatModTempMax_Value: accessed-variable=VeBTRR_T_HV_BatModTempMax.Value, variation-point={short-label=vpIN_VeBTRR_T_HV_BatModTempMax_Value, sw-syscond=1}
              IN_VeBTRR_T_HV_BatModTempMin_Value: accessed-variable=VeBTRR_T_HV_BatModTempMin.Value, variation-point={short-label=vpIN_VeBTRR_T_HV_BatModTempMin_Value, sw-syscond=1}
              IN_VeCPDR_b_LTAP_FunPer_ChkEnbl_Value: accessed-variable=VeCPDR_b_LTAP_FunPer_ChkEnbl.Value, variation-point={short-label=vpIN_VeCPDR_b_LTAP_FunPer_ChkEnbl_Value, sw-syscond=1}
              IN_VeCPDR_b_LTAP_FunPer_FltDtct_Value: accessed-variable=VeCPDR_b_LTAP_FunPer_FltDtct.Value, variation-point={short-label=vpIN_VeCPDR_b_LTAP_FunPer_FltDtct_Value, sw-syscond=1}
              IN_VeCSVR_b_VehSpdFA_Value: accessed-variable=VeCSVR_b_VehSpdFA.Value, variation-point={short-label=vpIN_VeCSVR_b_VehSpdFA_Value, sw-syscond=1}
              IN_VeCSVR_v_VehSpd_Value: accessed-variable=VeCSVR_v_VehSpd.Value, variation-point={short-label=vpIN_VeCSVR_v_VehSpd_Value, sw-syscond=1}
              IN_VeDFIR_b_DsblDiagFailSafe_Value: accessed-variable=VeDFIR_b_DsblDiagFailSafe.Value, variation-point={short-label=vpIN_VeDFIR_b_DsblDiagFailSafe_Value, sw-syscond=1}
              IN_VeDFIR_b_IsDiagGlobalConditionsValid_Value: accessed-variable=VeDFIR_b_IsDiagGlobalConditionsValid.Value, variation-point={short-label=vpIN_VeDFIR_b_IsDiagGlobalConditionsValid_Value, sw-syscond=1}
              IN_VeDFIR_b_PostCodeClrDiagDsbl_Value: accessed-variable=VeDFIR_b_PostCodeClrDiagDsbl.Value, variation-point={short-label=vpIN_VeDFIR_b_PostCodeClrDiagDsbl_Value, sw-syscond=1}
              IN_VeDMAB_y_StatusByte_AC_RefrigExpVlvActCtrCktPerf_Value: accessed-variable=VeDMAB_y_StatusByte_AC_RefrigExpVlvActCtrCktPerf.Value
              IN_VeDMAB_y_StatusByte_AC_RefrigPresSnsrAHi_Value: accessed-variable=VeDMAB_y_StatusByte_AC_RefrigPresSnsrAHi.Value
              IN_VeDMAB_y_StatusByte_AC_RefrigPresSnsrALo_Value: accessed-variable=VeDMAB_y_StatusByte_AC_RefrigPresSnsrALo.Value
              IN_VeDMAB_y_StatusByte_AC_RefrigPresSnsrAPerf_Value: accessed-variable=VeDMAB_y_StatusByte_AC_RefrigPresSnsrAPerf.Value
              IN_VeDMAB_y_StatusByte_BattCool_Value: accessed-variable=VeDMAB_y_StatusByte_BattCool.Value
              IN_VeDMAB_y_StatusByte_BattCoolLvlLow_Value: accessed-variable=VeDMAB_y_StatusByte_BattCoolLvlLow.Value
              IN_VeDMAB_y_StatusByte_BattCoolLvlSnsCkt_Value: accessed-variable=VeDMAB_y_StatusByte_BattCoolLvlSnsCkt.Value
              IN_VeDMAB_y_StatusByte_BattCoolPmpATempSnsrPerf_Value: accessed-variable=VeDMAB_y_StatusByte_BattCoolPmpATempSnsrPerf.Value
              IN_VeDMAB_y_StatusByte_BattCoolPmpHtrBTempSnsrPerf_Value: accessed-variable=VeDMAB_y_StatusByte_BattCoolPmpHtrBTempSnsrPerf.Value
              IN_VeDMAB_y_StatusByte_BattCoolPmpOveSpd_Value: accessed-variable=VeDMAB_y_StatusByte_BattCoolPmpOveSpd.Value
              IN_VeDMAB_y_StatusByte_BattCoolPmpPerf_Value: accessed-variable=VeDMAB_y_StatusByte_BattCoolPmpPerf.Value
              IN_VeDMAB_y_StatusByte_BattHeat_Value: accessed-variable=VeDMAB_y_StatusByte_BattHeat.Value
              IN_VeDMAB_y_StatusByte_CT_SnsrCktHi_Value: accessed-variable=VeDMAB_y_StatusByte_CT_SnsrCktHi.Value
              IN_VeDMAB_y_StatusByte_CT_SnsrCktLo_Value: accessed-variable=VeDMAB_y_StatusByte_CT_SnsrCktLo.Value
              IN_VeDMAB_y_StatusByte_CT_SnsrPerf_Value: accessed-variable=VeDMAB_y_StatusByte_CT_SnsrPerf.Value
              IN_VeDMAB_y_StatusByte_CommBusOff_Value: accessed-variable=VeDMAB_y_StatusByte_CommBusOff.Value
              IN_VeDMAB_y_StatusByte_CommBus_B_Off_Value: accessed-variable=VeDMAB_y_StatusByte_CommBus_B_Off.Value
              IN_VeDMAB_y_StatusByte_CoolCtrlVlv1Ckt_Value: accessed-variable=VeDMAB_y_StatusByte_CoolCtrlVlv1Ckt.Value
              IN_VeDMAB_y_StatusByte_CoolCtrlVlv1CktHi_Value: accessed-variable=VeDMAB_y_StatusByte_CoolCtrlVlv1CktHi.Value
              IN_VeDMAB_y_StatusByte_CoolCtrlVlv1CktLo_Value: accessed-variable=VeDMAB_y_StatusByte_CoolCtrlVlv1CktLo.Value
              IN_VeDMAB_y_StatusByte_CoolHeaterAPerf_Value: accessed-variable=VeDMAB_y_StatusByte_CoolHeaterAPerf.Value
              IN_VeDMAB_y_StatusByte_CoolOutTempSnsCkt_Value: accessed-variable=VeDMAB_y_StatusByte_CoolOutTempSnsCkt.Value
              IN_VeDMAB_y_StatusByte_CoolantHeaterBPerf_Value: accessed-variable=VeDMAB_y_StatusByte_CoolantHeaterBPerf.Value
              IN_VeDMAB_y_StatusByte_CoolantVlvA_Perf_Value: accessed-variable=VeDMAB_y_StatusByte_CoolantVlvA_Perf.Value
              IN_VeDMAB_y_StatusByte_CoolantVlvA_StkOpn_Value: accessed-variable=VeDMAB_y_StatusByte_CoolantVlvA_StkOpn.Value
              IN_VeDMAB_y_StatusByte_EACPerf_Value: accessed-variable=VeDMAB_y_StatusByte_EACPerf.Value
              IN_VeDMAB_y_StatusByte_HB_CT_SnsrPerf_Value: accessed-variable=VeDMAB_y_StatusByte_HB_CT_SnsrPerf.Value
              IN_VeDMAB_y_StatusByte_HB_PSC_CtrlValACktPerf_Value: accessed-variable=VeDMAB_y_StatusByte_HB_PSC_CtrlValACktPerf.Value
              IN_VeDMAB_y_StatusByte_HeatingElmntPerf_Value: accessed-variable=VeDMAB_y_StatusByte_HeatingElmntPerf.Value
              IN_VeDMAB_y_StatusByte_HiSpdFD_CAN11CommBus_Value: accessed-variable=VeDMAB_y_StatusByte_HiSpdFD_CAN11CommBus.Value
              IN_VeDMAB_y_StatusByte_HiSpdFD_CAN11CommBusPerf_Value: accessed-variable=VeDMAB_y_StatusByte_HiSpdFD_CAN11CommBusPerf.Value
              IN_VeDMAB_y_StatusByte_HiSpdFD_CAN3CommBus_Value: accessed-variable=VeDMAB_y_StatusByte_HiSpdFD_CAN3CommBus.Value
              IN_VeDMAB_y_StatusByte_HiSpdFD_CAN3CommBusPerf_Value: accessed-variable=VeDMAB_y_StatusByte_HiSpdFD_CAN3CommBusPerf.Value
              IN_VeDMAB_y_StatusByte_HiSpdFD_CAN5CommBus_Value: accessed-variable=VeDMAB_y_StatusByte_HiSpdFD_CAN5CommBus.Value
              IN_VeDMAB_y_StatusByte_HiSpdFD_CAN5CommBusPerf_Value: accessed-variable=VeDMAB_y_StatusByte_HiSpdFD_CAN5CommBusPerf.Value
              IN_VeDMAB_y_StatusByte_HybBatPacCooInlTemSenCirHig_Value: accessed-variable=VeDMAB_y_StatusByte_HybBatPacCooInlTemSenCirHig.Value
              IN_VeDMAB_y_StatusByte_HybBatPacCooInlTemSenCirLow_Value: accessed-variable=VeDMAB_y_StatusByte_HybBatPacCooInlTemSenCirLow.Value
              IN_VeDMAB_y_StatusByte_HybBatPacCooOutTemSenCir_Value: accessed-variable=VeDMAB_y_StatusByte_HybBatPacCooOutTemSenCir.Value
              IN_VeDMAB_y_StatusByte_HybBatPacCooOutTemSenCirHig_Value: accessed-variable=VeDMAB_y_StatusByte_HybBatPacCooOutTemSenCirHig.Value
              IN_VeDMAB_y_StatusByte_HybBattCooTempSnsrCPer_Value: accessed-variable=VeDMAB_y_StatusByte_HybBattCooTempSnsrCPer.Value
              IN_VeDMAB_y_StatusByte_HybBattCooTempSnsrDPer_Value: accessed-variable=VeDMAB_y_StatusByte_HybBattCooTempSnsrDPer.Value
              IN_VeDMAB_y_StatusByte_InvData_BECM_Value: accessed-variable=VeDMAB_y_StatusByte_InvData_BECM.Value
              IN_VeDMAB_y_StatusByte_InvData_BECM_CANC11_Value: accessed-variable=VeDMAB_y_StatusByte_InvData_BECM_CANC11.Value
              IN_VeDMAB_y_StatusByte_LIN{1..3}_BusOff_Value: accessed-variable=VeDMAB_y_StatusByte_LIN{1..3}_BusOff.Value
              IN_VeDMAB_y_StatusByte_LosCommBECM_A_Value: accessed-variable=VeDMAB_y_StatusByte_LosCommBECM_A.Value
              IN_VeDMAB_y_StatusByte_LosCommBECM_A_CANC11_Value: accessed-variable=VeDMAB_y_StatusByte_LosCommBECM_A_CANC11.Value
              IN_VeDMAB_y_StatusByte_LosCommHybPSCCtrlValA_Value: accessed-variable=VeDMAB_y_StatusByte_LosCommHybPSCCtrlValA.Value
              IN_VeDMAB_y_StatusByte_LostCommEAC_Value: accessed-variable=VeDMAB_y_StatusByte_LostCommEAC.Value
              IN_VeDMAB_y_StatusByte_LostCommECM_A_BusB_Value: accessed-variable=VeDMAB_y_StatusByte_LostCommECM_A_BusB.Value
              IN_VeDMAB_y_StatusByte_LostCommHB_CoolPmp_Value: accessed-variable=VeDMAB_y_StatusByte_LostCommHB_CoolPmp.Value
              IN_VeDMAB_y_StatusByte_LostCommHB_CooltHtr4_Value: accessed-variable=VeDMAB_y_StatusByte_LostCommHB_CooltHtr4.Value
              IN_VeDMAB_y_StatusByte_LostCommMtrElectCoolPmpA_Value: accessed-variable=VeDMAB_y_StatusByte_LostCommMtrElectCoolPmpA.Value
              IN_VeDMAB_y_StatusByte_MtrElect_CT_SnsrCktHi_Value: accessed-variable=VeDMAB_y_StatusByte_MtrElect_CT_SnsrCktHi.Value
              IN_VeDMAB_y_StatusByte_MtrElect_CT_SnsrCktLo_Value: accessed-variable=VeDMAB_y_StatusByte_MtrElect_CT_SnsrCktLo.Value
              IN_VeDMAB_y_StatusByte_MtrElect_CT_SnsrPerf_Value: accessed-variable=VeDMAB_y_StatusByte_MtrElect_CT_SnsrPerf.Value
              IN_VeDMAB_y_StatusByte_MtrElect_CoolPmpATempSnsrPerf_Value: accessed-variable=VeDMAB_y_StatusByte_MtrElect_CoolPmpATempSnsrPerf.Value
              IN_VeDMAB_y_StatusByte_MtrElect_CoolPumAOvrSpd_Value: accessed-variable=VeDMAB_y_StatusByte_MtrElect_CoolPumAOvrSpd.Value
              IN_VeDMAB_y_StatusByte_ThrmlRlyCtrlCkt_Value: accessed-variable=VeDMAB_y_StatusByte_ThrmlRlyCtrlCkt.Value
              IN_VeFSCR_b_RadFan_FltDtct_Value: accessed-variable=VeFSCR_b_RadFan_FltDtct.Value, variation-point={short-label=vpIN_VeFSCR_b_RadFan_FltDtct_Value, sw-syscond=1}
              IN_VeHTIR_P_HVC_Htr4PwrAct_Value: accessed-variable=VeHTIR_P_HVC_Htr4PwrAct.Value, variation-point={short-label=vpIN_VeHTIR_P_HVC_Htr4PwrAct_Value, sw-syscond=1}
              IN_VeHTIR_P_HVC_HtrPwrAct_Value: accessed-variable=VeHTIR_P_HVC_HtrPwrAct.Value, variation-point={short-label=vpIN_VeHTIR_P_HVC_HtrPwrAct_Value, sw-syscond=1}
              IN_VeHTIR_T_HVC_Htr4ClntOut_Temp_Value: accessed-variable=VeHTIR_T_HVC_Htr4ClntOut_Temp.Value
              IN_VeHTIR_b_HVC_Htr4ClntOut_Temp_FA_Value: accessed-variable=VeHTIR_b_HVC_Htr4ClntOut_Temp_FA.Value, variation-point={short-label=vpIN_VeHTIR_b_HVC_Htr4ClntOut_Temp_FA_Value, sw-syscond=1}
              IN_VeHTRR_P_HVC_HtrPwrLimit_Value: accessed-variable=VeHTRR_P_HVC_HtrPwrLimit.Value, variation-point={short-label=vpIN_VeHTRR_P_HVC_HtrPwrLimit_Value, sw-syscond=1}
              IN_VeHTRR_P_HV_Htr4PwrLimit_Value: accessed-variable=VeHTRR_P_HV_Htr4PwrLimit.Value, variation-point={short-label=vpIN_VeHTRR_P_HV_Htr4PwrLimit_Value, sw-syscond=1}
              IN_VePLTR_b_EstRollAngleAtZeroSpdFA_Value: accessed-variable=VePLTR_b_EstRollAngleAtZeroSpdFA.Value, variation-point={short-label=vpIN_VePLTR_b_EstRollAngleAtZeroSpdFA_Value, sw-syscond=1}
              IN_VePLTR_b_EstSlopeAngleFA_Value: accessed-variable=VePLTR_b_EstSlopeAngleFA.Value, variation-point={short-label=vpIN_VePLTR_b_EstSlopeAngleFA_Value, sw-syscond=1}
              IN_VePLTR_phi_EstRollAngleAtZeroSpd_Value: accessed-variable=VePLTR_phi_EstRollAngleAtZeroSpd.Value, variation-point={short-label=vpIN_VePLTR_phi_EstRollAngleAtZeroSpd_Value, sw-syscond=1}
              IN_VePLTR_phi_EstSlopeAngle_Value: accessed-variable=VePLTR_phi_EstSlopeAngle.Value, variation-point={short-label=vpIN_VePLTR_phi_EstSlopeAngle_Value, sw-syscond=1}
              IN_VePMIR_T_LTActvPumpTemp_Value: accessed-variable=VePMIR_T_LTActvPumpTemp.Value
              IN_VePMIR_b_LTActvPumpDryRun_FA_Value: accessed-variable=VePMIR_b_LTActvPumpDryRun_FA.Value, variation-point={short-label=vpIN_VePMIR_b_LTActvPumpDryRun_FA_Value, sw-syscond=1}
              IN_VePMIR_b_LTActvPumpTemp_FA_Value: accessed-variable=VePMIR_b_LTActvPumpTemp_FA.Value, variation-point={short-label=vpIN_VePMIR_b_LTActvPumpTemp_FA_Value, sw-syscond=1}
              IN_VePMIR_b_LTPsvPumpDryRun_FA_Value: accessed-variable=VePMIR_b_LTPsvPumpDryRun_FA.Value, variation-point={short-label=vpIN_VePMIR_b_LTPsvPumpDryRun_FA_Value, sw-syscond=1}
              IN_VePMIR_b_LTPsvPumpTemp_FA_Value: accessed-variable=VePMIR_b_LTPsvPumpTemp_FA.Value, variation-point={short-label=vpIN_VePMIR_b_LTPsvPumpTemp_FA_Value, sw-syscond=1}
              IN_VePMIR_e_LTActvPumpDryRun_Value: accessed-variable=VePMIR_e_LTActvPumpDryRun.Value, variation-point={short-label=vpIN_VePMIR_e_LTActvPumpDryRun_Value, sw-syscond=1}
              IN_VePMIR_n_LTActvPumpRPMAct_Value: accessed-variable=VePMIR_n_LTActvPumpRPMAct.Value, variation-point={short-label=vpIN_VePMIR_n_LTActvPumpRPMAct_Value, sw-syscond=1}
              IN_VePMTR_b_ThrmlSystRly_EnblCmnd_Value: accessed-variable=VePMTR_b_ThrmlSystRly_EnblCmnd.Value, variation-point={short-label=vpIN_VePMTR_b_ThrmlSystRly_EnblCmnd_Value, sw-syscond=1}
              IN_VeRCVR_Pct_HT_CabVlvSts_Value: accessed-variable=VeRCVR_Pct_HT_CabVlvSts.Value, variation-point={short-label=vpIN_VeRCVR_Pct_HT_CabVlvSts_Value, sw-syscond=1}
              IN_VeTAIR_Pct_FrWyVlv_PstnAct_Value: accessed-variable=VeTAIR_Pct_FrWyVlv_PstnAct.Value, variation-point={short-label=vpIN_VeTAIR_Pct_FrWyVlv_PstnAct_Value, sw-syscond=1}
              IN_VeTAIR_n_CompSpdFdb_Value: accessed-variable=VeTAIR_n_CompSpdFdb.Value, variation-point={short-label=vpIN_VeTAIR_n_CompSpdFdb_Value, sw-syscond=1}
              IN_VeTHMR_e_BatThrmlSt_Value: accessed-variable=VeTHMR_e_BatThrmlSt.Value, variation-point={short-label=vpIN_VeTHMR_e_BatThrmlSt_Value, sw-syscond=1}
              IN_VeTMIR_T_OnBrdChrg_ClntTmpIn_Value: accessed-variable=VeTMIR_T_OnBrdChrg_ClntTmpIn.Value, variation-point={short-label=vpIN_VeTMIR_T_OnBrdChrg_ClntTmpIn_Value, sw-syscond=1}
              IN_VeTRIR_T_HV_BatClntTmp2_In_Value: accessed-variable=VeTRIR_T_HV_BatClntTmp2_In.Value
              IN_VeTRIR_T_HV_BatClntTmpOut_Value: accessed-variable=VeTRIR_T_HV_BatClntTmpOut.Value
              IN_VeTRIR_T_HV_BatClntTmpOut2_Value: accessed-variable=VeTRIR_T_HV_BatClntTmpOut2.Value
              IN_VeTRIR_T_HV_BatClntTmp_In_Value: accessed-variable=VeTRIR_T_HV_BatClntTmp_In.Value
              IN_VeTRIR_U_BatBotlClnt_LoLvlVolt_Value: accessed-variable=VeTRIR_U_BatBotlClnt_LoLvlVolt.Value, variation-point={short-label=vpIN_VeTRIR_U_BatBotlClnt_LoLvlVolt_Value, sw-syscond=1}
              IN_VeTRIR_b_HV_BatClntTmp_In_FA_Value: accessed-variable=VeTRIR_b_HV_BatClntTmp_In_FA.Value, variation-point={short-label=vpIN_VeTRIR_b_HV_BatClntTmp_In_FA_Value, sw-syscond=1}
              IN_VeTRIR_b_HV_BatClntTmp_Out_FA_Value: accessed-variable=VeTRIR_b_HV_BatClntTmp_Out_FA.Value, variation-point={short-label=vpIN_VeTRIR_b_HV_BatClntTmp_Out_FA_Value, sw-syscond=1}
              IN_VeVLDR_b_HTCV_Leak_DiagEnbl_Value: accessed-variable=VeVLDR_b_HTCV_Leak_DiagEnbl.Value, variation-point={short-label=vpIN_VeVLDR_b_HTCV_Leak_DiagEnbl_Value, sw-syscond=1}
          data-send-points:
            28 x access:
              OUT_VeBRDR_b_LTAPDiag_Enbl_Value: accessed-variable=VeBRDR_b_LTAPDiag_Enbl.Value
              OUT_VeBRDR_b_LTAP_TmpFltDtct_Value: accessed-variable=VeBRDR_b_LTAP_TmpFltDtct.Value
              OUT_VeBRDR_b_BTOSDiag_Enbl_Value: accessed-variable=VeBRDR_b_BTOSDiag_Enbl.Value
              OUT_VeBRDR_b_HV_BTOS_FltDtct_Value: accessed-variable=VeBRDR_b_HV_BTOS_FltDtct.Value
              OUT_VeBRDR_b_HV_BTIS_FltDtct_Value: accessed-variable=VeBRDR_b_HV_BTIS_FltDtct.Value
              OUT_VeBRDR_b_BHOSDiag_Enbl_Value: accessed-variable=VeBRDR_b_BHOSDiag_Enbl.Value
              OUT_VeBRDR_b_HV_BHOS_FltDtct_Value: accessed-variable=VeBRDR_b_HV_BHOS_FltDtct.Value
              OUT_VeBRDR_b_BTOS2Diag_Enbl_Value: accessed-variable=VeBRDR_b_BTOS2Diag_Enbl.Value
              OUT_VeBRDR_b_HV_BTOS2_FltDtct_Value: accessed-variable=VeBRDR_b_HV_BTOS2_FltDtct.Value
              OUT_VeBRDR_e_HV_Bat_CltLvlLo_Value: accessed-variable=VeBRDR_e_HV_Bat_CltLvlLo.Value
              OUT_VeBRDR_b_LTAP_Rqt_LoLv_Diag_Value: accessed-variable=VeBRDR_b_LTAP_Rqt_LoLv_Diag.Value
              OUT_VeBRDR_b_IUMPR_BTISPerf_Value: accessed-variable=VeBRDR_b_IUMPR_BTISPerf.Value
              OUT_VeBRDR_b_IUMPR_BTOSPerf_Value: accessed-variable=VeBRDR_b_IUMPR_BTOSPerf.Value
              OUT_VeBRDR_b_IUMPR_LTAP_TmpPerf_Value: accessed-variable=VeBRDR_b_IUMPR_LTAP_TmpPerf.Value
              OUT_VeBRDR_b_IUMPR_BHOSPerf_Value: accessed-variable=VeBRDR_b_IUMPR_BHOSPerf.Value
              OUT_VeBRDR_b_IUMPR_BattCoolPerf_Value: accessed-variable=VeBRDR_b_IUMPR_BattCoolPerf.Value
              OUT_VeBRDR_b_IUMPR_BattHeatPerf_Value: accessed-variable=VeBRDR_b_IUMPR_BattHeatPerf.Value
              OUT_VeBRDR_b_HV_BTIS2_FltDtct_Value: accessed-variable=VeBRDR_b_HV_BTIS2_FltDtct.Value
              OUT_VeBRDR_e_FaultSts_BattCoolPmpATempSnsrPerf_Value: accessed-variable=VeBRDR_e_FaultSts_BattCoolPmpATempSnsrPerf.Value
              OUT_VeBRDR_e_FaultSts_BattCoolPmpHtrBTempSnsrPerf_Value: accessed-variable=VeBRDR_e_FaultSts_BattCoolPmpHtrBTempSnsrPerf.Value
              OUT_VeBRDR_e_FaultSts_HB_CT_SnsrPerf_Value: accessed-variable=VeBRDR_e_FaultSts_HB_CT_SnsrPerf.Value
              OUT_VeBRDR_e_FaultSts_HybBattCooTempSnsrCPer_Value: accessed-variable=VeBRDR_e_FaultSts_HybBattCooTempSnsrCPer.Value
              OUT_VeBRDR_e_FaultSts_CoolOutTempSnsCkt_Value: accessed-variable=VeBRDR_e_FaultSts_CoolOutTempSnsCkt.Value
              OUT_VeBRDR_e_FaultSts_HybBattCooTempSnsrDPer_Value: accessed-variable=VeBRDR_e_FaultSts_HybBattCooTempSnsrDPer.Value
              OUT_VeBRDR_e_FaultSts_BattHeat_Value: accessed-variable=VeBRDR_e_FaultSts_BattHeat.Value
              OUT_VeBRDR_e_FaultSts_BattCool_Value: accessed-variable=VeBRDR_e_FaultSts_BattCool.Value
              OUT_VeBRDR_e_FaultSts_BattCoolLvlLow_Value: accessed-variable=VeBRDR_e_FaultSts_BattCoolLvlLow.Value
              OUT_VeBRDR_e_FaultSts_BattCoolLvlSnsCkt_Value: accessed-variable=VeBRDR_e_FaultSts_BattCoolLvlSnsCkt.Value
        BRDR_PwrOn
          data-receive-point-by-arguments:
            10 x access:
              IN_NeBRDR_Cnt_ChillPerf_MFOP_Rx_NeBRDR_Cnt_ChillPerf_MFOP: accessed-variable=NeBRDR_Cnt_ChillPerf_MFOP_Rx.NeBRDR_Cnt_ChillPerf_MFOP
              IN_NeBRDR_Cnt_HVBatCltLvLo_OC_MFOP_Rx_NeBRDR_Cnt_HVBatCltLvLo_OC_MFOP: accessed-variable=NeBRDR_Cnt_HVBatCltLvLo_OC_MFOP_Rx.NeBRDR_Cnt_HVBatCltLvLo_OC_MFOP
              IN_NeBRDR_Cnt_HVBatCltLvlSnsCkt_MFOP_Rx_NeBRDR_Cnt_HVBatCltLvlSnsCkt_MFOP: accessed-variable=NeBRDR_Cnt_HVBatCltLvlSnsCkt_MFOP_Rx.NeBRDR_Cnt_HVBatCltLvlSnsCkt_MFOP
              IN_NeBRDR_Cnt_HV_BHOS_MFOP_Rx_NeBRDR_Cnt_HV_BHOS_MFOP: accessed-variable=NeBRDR_Cnt_HV_BHOS_MFOP_Rx.NeBRDR_Cnt_HV_BHOS_MFOP
              IN_NeBRDR_Cnt_HV_BTIS2_MFOP_Rx_NeBRDR_Cnt_HV_BTIS2_MFOP: accessed-variable=NeBRDR_Cnt_HV_BTIS2_MFOP_Rx.NeBRDR_Cnt_HV_BTIS2_MFOP
              IN_NeBRDR_Cnt_HV_BTIS_MFOP_Rx_NeBRDR_Cnt_HV_BTIS_MFOP: accessed-variable=NeBRDR_Cnt_HV_BTIS_MFOP_Rx.NeBRDR_Cnt_HV_BTIS_MFOP
              IN_NeBRDR_Cnt_HV_BTOS2_MFOP_Rx_NeBRDR_Cnt_HV_BTOS2_MFOP: accessed-variable=NeBRDR_Cnt_HV_BTOS2_MFOP_Rx.NeBRDR_Cnt_HV_BTOS2_MFOP
              IN_NeBRDR_Cnt_HV_BTOS_MFOP_Rx_NeBRDR_Cnt_HV_BTOS_MFOP: accessed-variable=NeBRDR_Cnt_HV_BTOS_MFOP_Rx.NeBRDR_Cnt_HV_BTOS_MFOP
              IN_NeBRDR_Cnt_HeatExPerf_MFOP_Rx_NeBRDR_Cnt_HeatExPerf_MFOP: accessed-variable=NeBRDR_Cnt_HeatExPerf_MFOP_Rx.NeBRDR_Cnt_HeatExPerf_MFOP
              IN_NeBRDR_Cnt_LTAP_MFOP_Rx_NeBRDR_Cnt_LTAP_MFOP: accessed-variable=NeBRDR_Cnt_LTAP_MFOP_Rx.NeBRDR_Cnt_LTAP_MFOP
          data-send-points:
            28 x access:
              OUT_VeBRDR_b_LTAPDiag_Enbl_Value: accessed-variable=VeBRDR_b_LTAPDiag_Enbl.Value
              OUT_VeBRDR_b_LTAP_TmpFltDtct_Value: accessed-variable=VeBRDR_b_LTAP_TmpFltDtct.Value
              OUT_VeBRDR_b_BTOSDiag_Enbl_Value: accessed-variable=VeBRDR_b_BTOSDiag_Enbl.Value
              OUT_VeBRDR_b_HV_BTOS_FltDtct_Value: accessed-variable=VeBRDR_b_HV_BTOS_FltDtct.Value
              OUT_VeBRDR_b_HV_BTIS_FltDtct_Value: accessed-variable=VeBRDR_b_HV_BTIS_FltDtct.Value
              OUT_VeBRDR_b_BHOSDiag_Enbl_Value: accessed-variable=VeBRDR_b_BHOSDiag_Enbl.Value
              OUT_VeBRDR_b_HV_BHOS_FltDtct_Value: accessed-variable=VeBRDR_b_HV_BHOS_FltDtct.Value
              OUT_VeBRDR_b_BTOS2Diag_Enbl_Value: accessed-variable=VeBRDR_b_BTOS2Diag_Enbl.Value
              OUT_VeBRDR_b_HV_BTOS2_FltDtct_Value: accessed-variable=VeBRDR_b_HV_BTOS2_FltDtct.Value
              OUT_VeBRDR_e_HV_Bat_CltLvlLo_Value: accessed-variable=VeBRDR_e_HV_Bat_CltLvlLo.Value
              OUT_VeBRDR_b_LTAP_Rqt_LoLv_Diag_Value: accessed-variable=VeBRDR_b_LTAP_Rqt_LoLv_Diag.Value
              OUT_VeBRDR_b_IUMPR_BTISPerf_Value: accessed-variable=VeBRDR_b_IUMPR_BTISPerf.Value
              OUT_VeBRDR_b_IUMPR_BTOSPerf_Value: accessed-variable=VeBRDR_b_IUMPR_BTOSPerf.Value
              OUT_VeBRDR_b_IUMPR_LTAP_TmpPerf_Value: accessed-variable=VeBRDR_b_IUMPR_LTAP_TmpPerf.Value
              OUT_VeBRDR_b_IUMPR_BHOSPerf_Value: accessed-variable=VeBRDR_b_IUMPR_BHOSPerf.Value
              OUT_VeBRDR_b_IUMPR_BattCoolPerf_Value: accessed-variable=VeBRDR_b_IUMPR_BattCoolPerf.Value
              OUT_VeBRDR_b_IUMPR_BattHeatPerf_Value: accessed-variable=VeBRDR_b_IUMPR_BattHeatPerf.Value
              OUT_VeBRDR_b_HV_BTIS2_FltDtct_Value: accessed-variable=VeBRDR_b_HV_BTIS2_FltDtct.Value
              OUT_VeBRDR_e_FaultSts_BattCoolPmpATempSnsrPerf_Value: accessed-variable=VeBRDR_e_FaultSts_BattCoolPmpATempSnsrPerf.Value
              OUT_VeBRDR_e_FaultSts_BattCoolPmpHtrBTempSnsrPerf_Value: accessed-variable=VeBRDR_e_FaultSts_BattCoolPmpHtrBTempSnsrPerf.Value
              OUT_VeBRDR_e_FaultSts_HB_CT_SnsrPerf_Value: accessed-variable=VeBRDR_e_FaultSts_HB_CT_SnsrPerf.Value
              OUT_VeBRDR_e_FaultSts_HybBattCooTempSnsrCPer_Value: accessed-variable=VeBRDR_e_FaultSts_HybBattCooTempSnsrCPer.Value
              OUT_VeBRDR_e_FaultSts_CoolOutTempSnsCkt_Value: accessed-variable=VeBRDR_e_FaultSts_CoolOutTempSnsCkt.Value
              OUT_VeBRDR_e_FaultSts_HybBattCooTempSnsrDPer_Value: accessed-variable=VeBRDR_e_FaultSts_HybBattCooTempSnsrDPer.Value
              OUT_VeBRDR_e_FaultSts_BattHeat_Value: accessed-variable=VeBRDR_e_FaultSts_BattHeat.Value
              OUT_VeBRDR_e_FaultSts_BattCool_Value: accessed-variable=VeBRDR_e_FaultSts_BattCool.Value
              OUT_VeBRDR_e_FaultSts_BattCoolLvlLow_Value: accessed-variable=VeBRDR_e_FaultSts_BattCoolLvlLow.Value
              OUT_VeBRDR_e_FaultSts_BattCoolLvlSnsCkt_Value: accessed-variable=VeBRDR_e_FaultSts_BattCoolLvlSnsCkt.Value
        BRDR_PwrOff
          data-send-points:
            10 x access:
              OUT_NeBRDR_Cnt_ChillPerf_MFOP_NeBRDR_Cnt_ChillPerf_MFOP: accessed-variable=NeBRDR_Cnt_ChillPerf_MFOP.NeBRDR_Cnt_ChillPerf_MFOP
              OUT_NeBRDR_Cnt_HVBatCltLvLo_OC_MFOP_NeBRDR_Cnt_HVBatCltLvLo_OC_MFOP: accessed-variable=NeBRDR_Cnt_HVBatCltLvLo_OC_MFOP.NeBRDR_Cnt_HVBatCltLvLo_OC_MFOP
              OUT_NeBRDR_Cnt_HVBatCltLvlSnsCkt_MFOP_NeBRDR_Cnt_HVBatCltLvlSnsCkt_MFOP: accessed-variable=NeBRDR_Cnt_HVBatCltLvlSnsCkt_MFOP.NeBRDR_Cnt_HVBatCltLvlSnsCkt_MFOP
              OUT_NeBRDR_Cnt_HV_BTIS2_MFOP_NeBRDR_Cnt_HV_BTIS2_MFOP: accessed-variable=NeBRDR_Cnt_HV_BTIS2_MFOP.NeBRDR_Cnt_HV_BTIS2_MFOP
              OUT_NeBRDR_Cnt_HV_BTOS2_MFOP_NeBRDR_Cnt_HV_BTOS2_MFOP: accessed-variable=NeBRDR_Cnt_HV_BTOS2_MFOP.NeBRDR_Cnt_HV_BTOS2_MFOP
              OUT_NeBRDR_Cnt_HeatExPerf_MFOP_NeBRDR_Cnt_HeatExPerf_MFOP: accessed-variable=NeBRDR_Cnt_HeatExPerf_MFOP.NeBRDR_Cnt_HeatExPerf_MFOP
              OUT_NeBRDR_Cnt_HV_BTIS_MFOP_NeBRDR_Cnt_HV_BTIS_MFOP: accessed-variable=NeBRDR_Cnt_HV_BTIS_MFOP.NeBRDR_Cnt_HV_BTIS_MFOP
              OUT_NeBRDR_Cnt_HV_BTOS_MFOP_NeBRDR_Cnt_HV_BTOS_MFOP: accessed-variable=NeBRDR_Cnt_HV_BTOS_MFOP.NeBRDR_Cnt_HV_BTOS_MFOP
              OUT_NeBRDR_Cnt_LTAP_MFOP_NeBRDR_Cnt_LTAP_MFOP: accessed-variable=NeBRDR_Cnt_LTAP_MFOP.NeBRDR_Cnt_LTAP_MFOP
              OUT_NeBRDR_Cnt_HV_BHOS_MFOP_NeBRDR_Cnt_HV_BHOS_MFOP: accessed-variable=NeBRDR_Cnt_HV_BHOS_MFOP.NeBRDR_Cnt_HV_BHOS_MFOP
      22 x variation point proxy, all with category=CONDITION:
        Variant_BRDR_1: condition-access=1
        Variant_BRDR_12: condition-access=1
        Variant_BRDR_14: condition-access=1
        Variant_BRDR_{15..18}: condition-access=0
        Variant_BRDR_19: condition-access=1
        Variant_BRDR_2: condition-access=0
        Variant_BRDR_21: condition-access=1
        Variant_BRDR_23: condition-access=1
        Variant_BRDR_24: condition-access=0
        Variant_BRDR_28: condition-access=0
        Variant_BRDR_3: condition-access=0
        Variant_BRDR_31: condition-access=0
        Variant_BRDR_33: condition-access=1
        Variant_BRDR_34: condition-access=0
        Variant_BRDR_35: condition-access=1
        Variant_BRDR_4: condition-access=0
        Variant_BRDR_5: condition-access=0
        Variant_BRDR_6: condition-access=1
        Variant_BRDR_8: condition-access=1
